# C2000_Enhanced_Debug_Global_Registers register map
Vendor: Texas Instruments
Peripheral module from a debugger description file (folder C2000).
Address unit: 16 bits
Registers are 16-bit, read-write, reset 0x0 unless marked. A register's access mark holds for its fields unless they carry their own. Offsets are as the file gives them; lines under a group give offsets from that group; [hi:lo] are bit positions; {n}, {i} and the like mark numbered series; 'fields as' and 'values as' point back to an identical list; <NAME> marks a mode.

## EnhancedDebugGlobalRegs — Enhanced Debug Global Registers
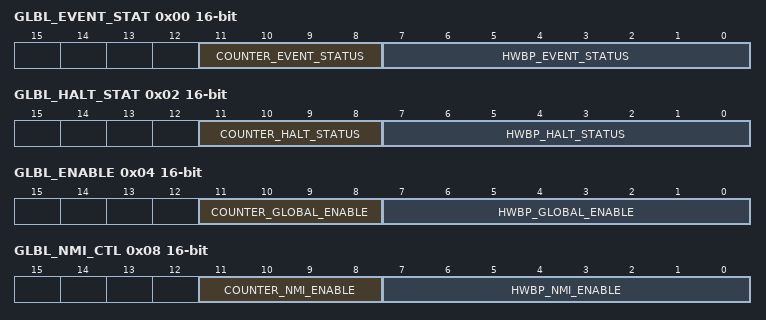
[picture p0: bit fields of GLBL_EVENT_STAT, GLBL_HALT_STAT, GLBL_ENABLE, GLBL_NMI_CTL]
0x00 GLBL_EVENT_STAT ro — Global event status
  [11:8] COUNTER_EVENT_STATUS — Counter Module Event Status
  [7:0] HWBP_EVENT_STATUS — Bus Comparator Module Event Status
0x02 GLBL_HALT_STAT ro — Global halt status
  [11:8] COUNTER_HALT_STATUS — Counter Module Halt Status
  [7:0] HWBP_HALT_STATUS — Bus Comparator Module Halt Status
0x04 GLBL_ENABLE — Global module enable
  [11:8] COUNTER_GLOBAL_ENABLE — Counter Module Global Enable
  [7:0] HWBP_GLOBAL_ENABLE — Bus Comparator Module Global Enable
0x06 CTM_GLBL_RESET — Global counter reset
  [3:0] COUNTER_GLOBAL_RESET — Global Reset for the counters
0x08 GLBL_NMI_CTL — Global Debug NMI control
  [11:8] COUNTER_NMI_ENABLE — Reserved for future use
  [7:0] HWBP_NMI_ENABLE — Reserved for future use
0x0A GLBL_OWNER — Global Ownership
  [1:0] OWNER — Global Ownership Bits
